# SWM341 register map
File version: 1.0
CPU: CM0 r1p0, little endian, MPU, FPU, 2 interrupt priority bits
Registers are 32-bit, read-write, no defined reset value unless marked. A register's access mark holds for its fields unless they carry their own. Offsets are from the block's base; [hi:lo] are bit positions; lines under a group give offsets from that group; {n}, {i} and the like mark numbered series; 'fields as' and 'values as' point back to an identical list.

## DMA2D — Registers group
Base 0x4000C000
0x00 IF
  [1] DONE
0x04 IE
  [1] DONE
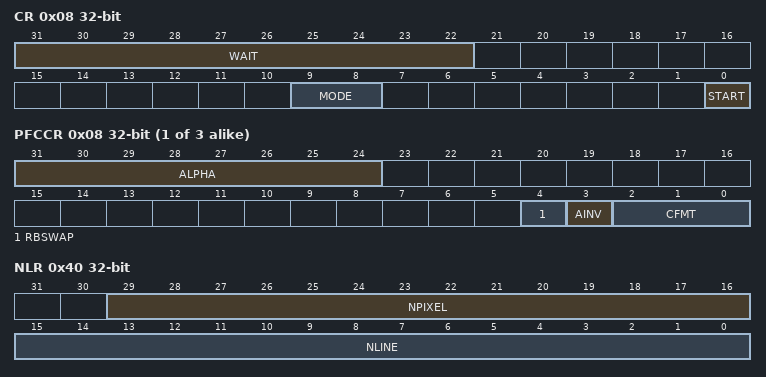
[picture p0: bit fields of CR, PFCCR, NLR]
0x08 CR
  [31:22] WAIT, [9:8] MODE, [0] START
{0x10+0x10*i} L{i} group (i=0..2) — register cluster
  0x00 MAR
  0x04 OR
  0x08 PFCCR
    [31:24] ALPHA, [4] RBSWAP, [3] AINV, [2:0] CFMT
  0x0C COLOR
0x40 NLR
  [29:16] NPIXEL, [15:0] NLINE

## DAC — Registers group
Base 0x4004C000
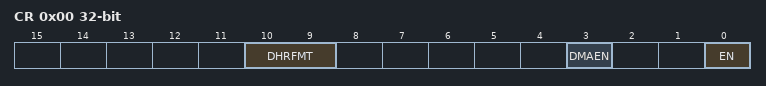
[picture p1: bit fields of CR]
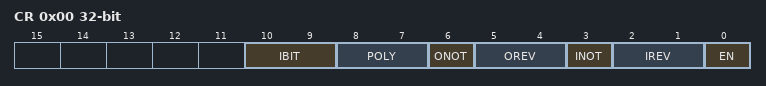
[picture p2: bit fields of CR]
0x00 CR
  [10:9] DHRFMT, [3] DMAEN, [0] EN
0x04 SR ro
  [0] DHRFULL
0x08 SWTRG wo
0x0C DHR

## CRC — Registers group
Base 0x40002800
0x00 CR
  [10:9] IBIT, [8:7] POLY, [6] ONOT, [5:4] OREV, [3] INOT, [2:1] IREV, [0] EN
0x04 DATAIN wo
0x08 INIVAL
0x0C RESULT ro

## CORDIC — Registers group
Base 0x40003000
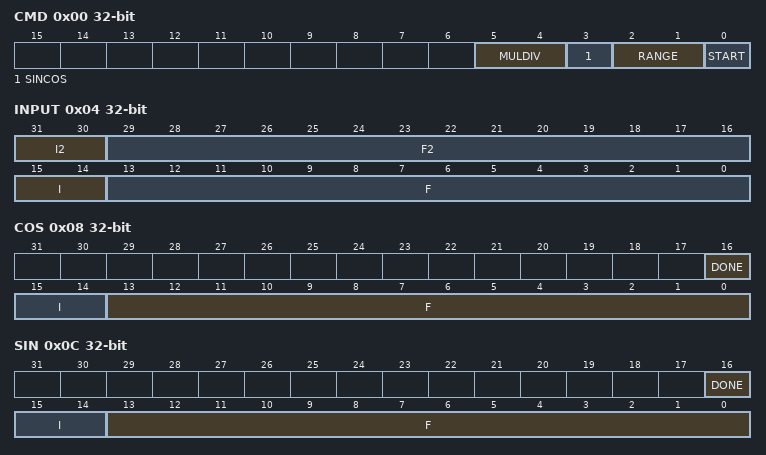
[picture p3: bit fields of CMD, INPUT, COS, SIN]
0x00 CMD
  [5:4] MULDIV, [3] SINCOS, [2:1] RANGE, [0] START
0x04 INPUT
  [31:30] I2, [29:16] F2, [15:14] I, [13:0] F
0x08 COS
  [16] DONE, [15:14] I, [13:0] F
0x0C SIN
  [16] DONE, [15:14] I, [13:0] F
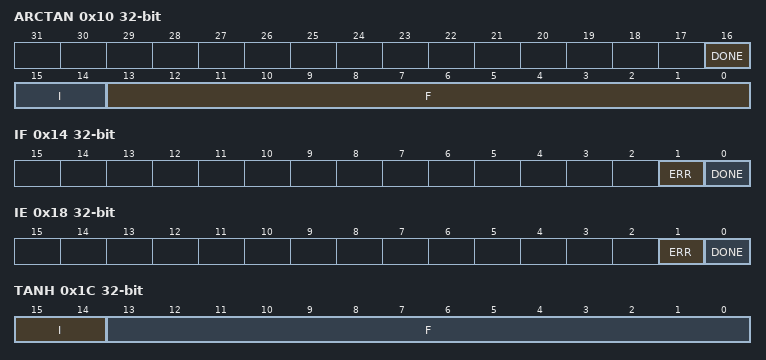
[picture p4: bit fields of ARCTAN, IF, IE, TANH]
0x10 ARCTAN
  [16] DONE, [15:14] I, [13:0] F
0x14 IF
  [1] ERR, [0] DONE
0x18 IE
  [1] ERR, [0] DONE
0x1C TANH
  [15:14] I, [13:0] F

## DIV — Registers group
Base 0x40003800
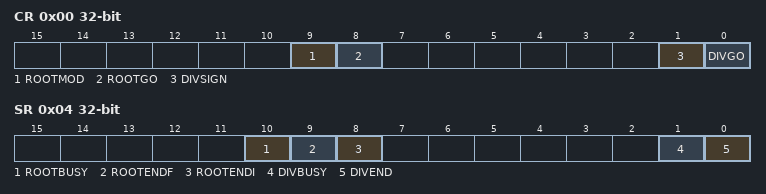
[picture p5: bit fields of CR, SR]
0x00 CR
  [9] ROOTMOD, [8] ROOTGO, [1] DIVSIGN, [0] DIVGO
0x04 SR
  [10] ROOTBUSY, [9] ROOTENDF, [8] ROOTENDI, [1] DIVBUSY, [0] DIVEND
0x10 DIVIDEND
0x14 DIVISOR
0x18 QUO
0x1C REMAIN
0x20 RADICAND
0x24 ROOT

## RTC — Registers group
Base 0x4004B800
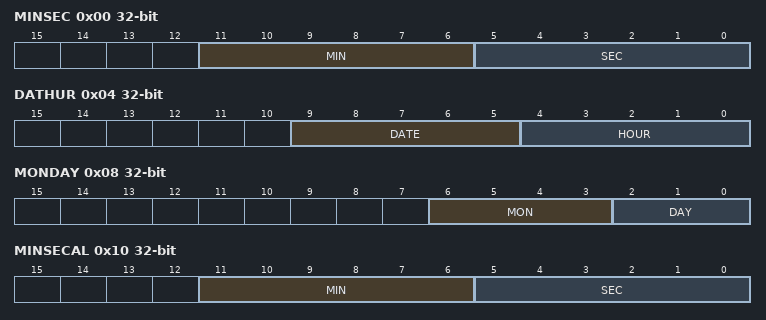
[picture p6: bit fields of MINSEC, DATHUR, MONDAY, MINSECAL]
0x00 MINSEC
  [11:6] MIN, [5:0] SEC
0x04 DATHUR
  [9:5] DATE, [4:0] HOUR
0x08 MONDAY
  [6:3] MON, [2:0] DAY
0x0C YEAR
0x10 MINSECAL
  [11:6] MIN, [5:0] SEC
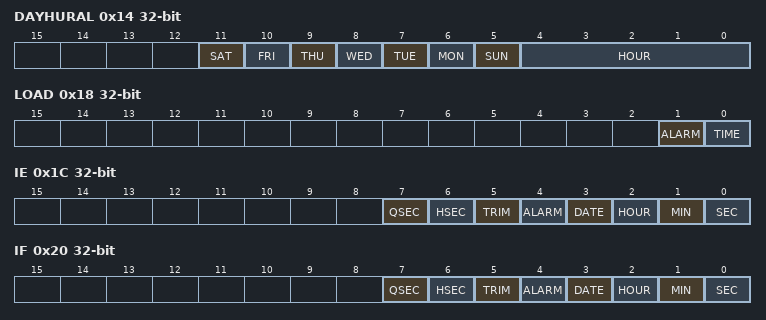
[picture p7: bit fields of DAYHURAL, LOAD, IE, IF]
0x14 DAYHURAL
  [11] SAT, [10] FRI, [9] THU, [8] WED, [7] TUE, [6] MON, [5] SUN, [4:0] HOUR
0x18 LOAD
  [1] ALARM, [0] TIME
0x1C IE
  [7] QSEC, [6] HSEC, [5] TRIM, [4] ALARM, [3] DATE, [2] HOUR, [1] MIN, [0] SEC
0x20 IF
  fields as IE
0x24 EN
0x28 CFGABLE
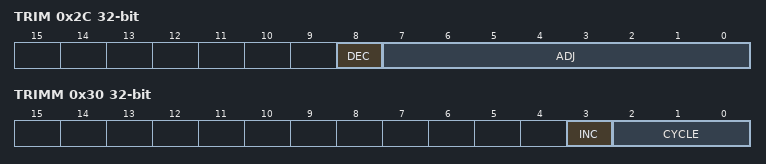
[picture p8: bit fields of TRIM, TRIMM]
0x2C TRIM
  [8] DEC, [7:0] ADJ
0x30 TRIMM
  [3] INC, [2:0] CYCLE

## WDT — Registers group
Base 0x400A0800
0x00 RSTVAL
0x04 INTVAL
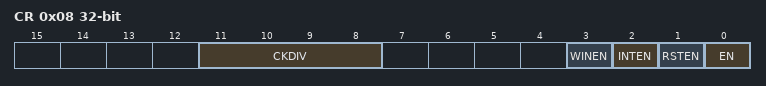
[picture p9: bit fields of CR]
0x08 CR
  [11:8] CKDIV, [3] WINEN, [2] INTEN, [1] RSTEN, [0] EN
0x0C IF
0x10 FEED

## QEI — Registers group
Base 0x4004C800
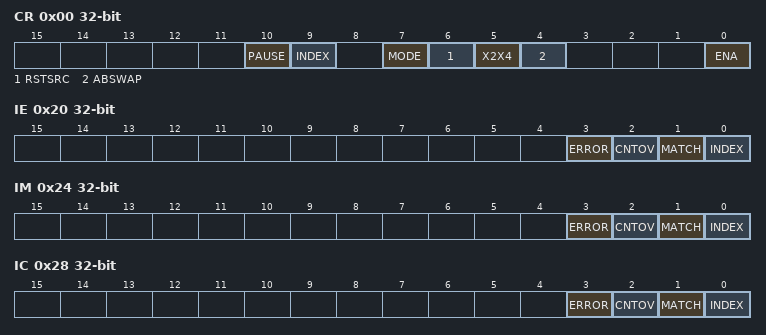
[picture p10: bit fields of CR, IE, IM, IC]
0x00 CR
  [10] PAUSE, [9] INDEX, [7] MODE, [6] RSTSRC, [5] X2X4, [4] ABSWAP, [0] ENA
0x04 POSCNT
0x08 MAXCNT
0x20 IE
  [3] ERROR, [2] CNTOV, [1] MATCH, [0] INDEX
0x24 IM
  [3] ERROR, [2] CNTOV, [1] MATCH, [0] INDEX
0x28 IC wo
  [3] ERROR, [2] CNTOV, [1] MATCH, [0] INDEX
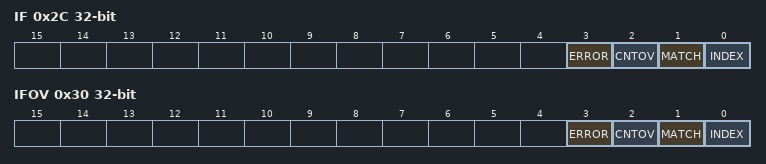
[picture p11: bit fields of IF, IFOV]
0x2C IF ro
  [3] ERROR, [2] CNTOV, [1] MATCH, [0] INDEX
0x30 IFOV
  [3] ERROR, [2] CNTOV, [1] MATCH, [0] INDEX

## FMC — Registers group
Base 0x4004A000
0x00 DATA
0x04 ADDR
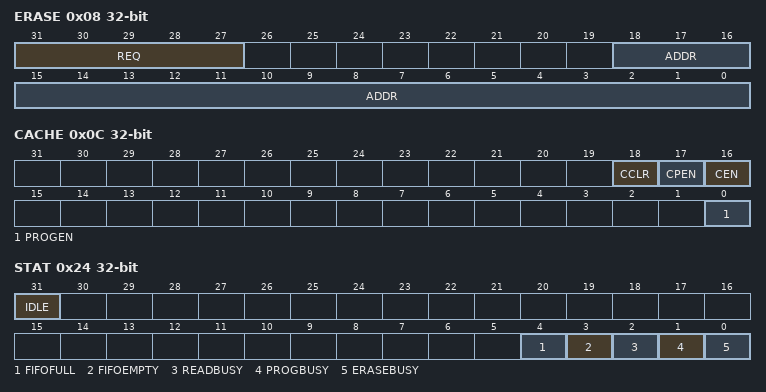
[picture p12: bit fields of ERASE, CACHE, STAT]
0x08 ERASE
  [31:27] REQ, [18:0] ADDR
0x0C CACHE
  [18] CCLR, [17] CPEN, [16] CEN, [0] PROGEN
{0x10+4i} CFG{i} (i=0..4)
0x24 STAT
  [31] IDLE, [4] FIFOFULL, [3] FIFOEMPTY, [2] READBUSY, [1] PROGBUSY, [0] ERASEBUSY

## SFC — Registers group
Base 0x4004A800
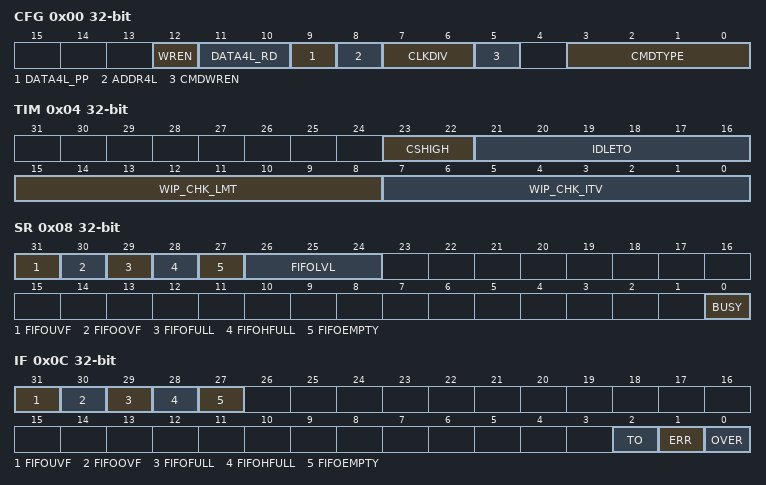
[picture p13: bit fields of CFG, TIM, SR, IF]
0x00 CFG
  [12] WREN, [11:10] DATA4L_RD, [9] DATA4L_PP, [8] ADDR4L, [7:6] CLKDIV, [5] CMDWREN, [3:0] CMDTYPE
0x04 TIM
  [23:22] CSHIGH, [21:16] IDLETO, [15:8] WIP_CHK_LMT, [7:0] WIP_CHK_ITV
0x08 SR ro
  [31] FIFOUVF, [30] FIFOOVF, [29] FIFOFULL, [28] FIFOHFULL, [27] FIFOEMPTY, [26:24] FIFOLVL, [0] BUSY
0x0C IF
  [31] FIFOUVF, [30] FIFOOVF, [29] FIFOFULL, [28] FIFOHFULL, [27] FIFOEMPTY, [2] TO, [1] ERR, [0] OVER
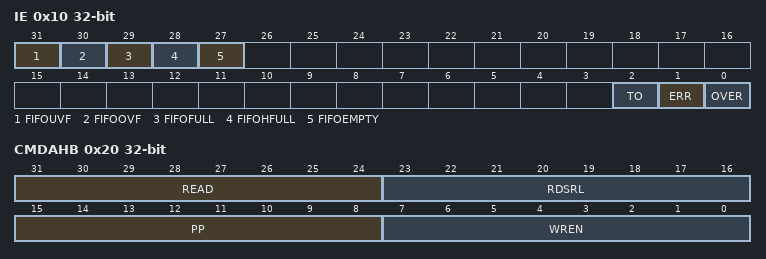
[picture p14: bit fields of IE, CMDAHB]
0x10 IE
  fields as IF
0x14 GO
0x18 ADDR
0x1C DATA
0x20 CMDAHB
  [31:24] READ, [23:16] RDSRL, [15:8] PP, [7:0] WREN
0x24 CMD

## JPEG — Registers group
Base 0x4000B000
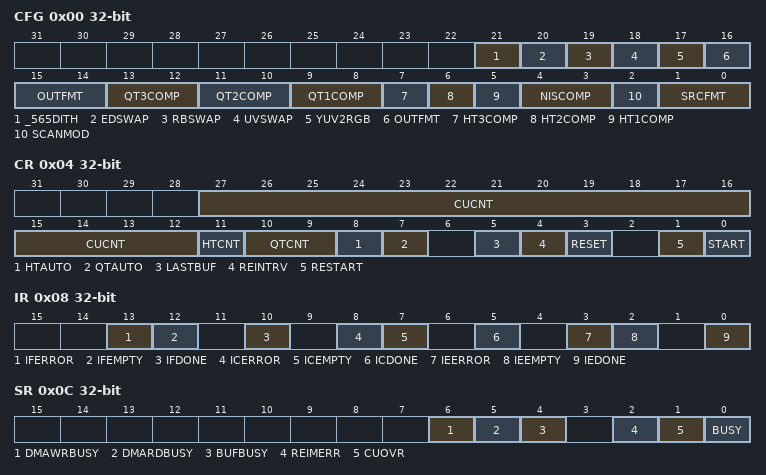
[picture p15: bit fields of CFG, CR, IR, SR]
0x00 CFG
  [21] _565DITH, [20] EDSWAP, [19] RBSWAP, [18] UVSWAP, [17] YUV2RGB, [16:14] OUTFMT, [13:12] QT3COMP, [11:10] QT2COMP, [9:8] QT1COMP, [7] HT3COMP, [6] HT2COMP, [5] HT1COMP, [4:3] NISCOMP, [2] SCANMOD, [1:0] SRCFMT
0x04 CR
  [27:12] CUCNT, [11] HTCNT, [10:9] QTCNT, [8] HTAUTO, [7] QTAUTO, [5] LASTBUF, [4] REINTRV, [3] RESET, [1] RESTART, [0] START
0x08 IR
  [13] IFERROR, [12] IFEMPTY, [10] IFDONE, [8] ICERROR, [7] ICEMPTY, [5] ICDONE, [3] IEERROR, [2] IEEMPTY, [0] IEDONE
0x0C SR
  [6] DMAWRBUSY, [5] DMARDBUSY, [4] BUFBUSY, [2] REIMERR, [1] CUOVR, [0] BUSY
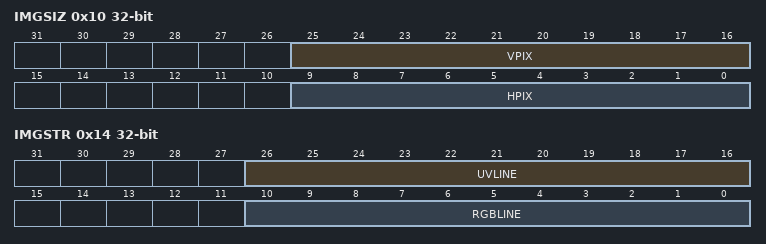
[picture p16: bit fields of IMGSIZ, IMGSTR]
0x10 IMGSIZ
  [25:16] VPIX, [9:0] HPIX
0x14 IMGSTR
  [26:16] UVLINE, [10:0] RGBLINE
0x18 CSBASE
0x1C YBASE
0x1C RGBASE (alternate view of YBASE)
0x20 UBASE
0x24 VBASE
0x28 QTBASE
0x2C HTBASE
0x30 CODLEN
{0x100+4i} QTABLE0_[{i}] (i=0..15) wo
{0x140+4i} QTABLE1_[{i}] (i=0..15) wo
{0x180+4i} QTABLE2_[{i}] (i=0..15) wo
0x200 HTABLE0 group — register cluster
  {0x0+4j} DC_CODEWORD[{j}] (j=0..5) wo
  {0x18+4j} DC_CODELEN[{j}] (j=0..1) wo
  {0x20+4j} DC_CODEVAL[{j}] (j=0..1) wo
  {0x28+4j} AC_CODEWORD[{j}] (j=0..7) wo
  {0x48+4j} AC_CODEADDR[{j}] (j=0..3) wo
  {0x58+4j} AC_CODEVAL[{j}] (j=0..40) wo
0x300 HTABLE1 group — register cluster
  {0x0+4j} DC_CODEWORD[{j}] (j=0..5) wo
  {0x18+4j} DC_CODELEN[{j}] (j=0..1) wo
  {0x20+4j} DC_CODEVAL[{j}] (j=0..1) wo
  {0x28+4j} AC_CODEWORD[{j}] (j=0..7) wo
  {0x48+4j} AC_CODEADDR[{j}] (j=0..3) wo
  {0x58+4j} AC_CODEVAL[{j}] (j=0..40) wo
